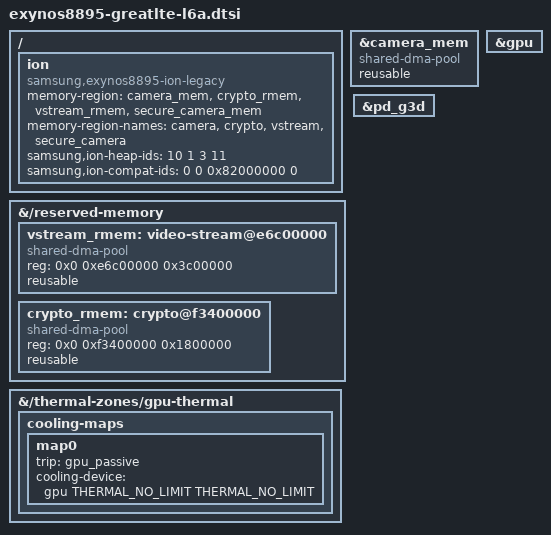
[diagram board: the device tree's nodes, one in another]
// SPDX-License-Identifier: GPL-2.0 OR BSD-3-Clause
/*
 * Samsung Galaxy Note 8 (greatlte, SM-N950N) board DT, part "l6a":
 * L6A graphics: GPU, ION (L6A 4).
 *
 * Included at the end of exynos8895-greatlte.dts, after L0's nodes, in the merge
 * order of FULL_IMAGE_PLAN.md 2.2. Owner: WP-6A; no other work package edits this
 * file (plan 2.3 rule D1). A node that two parts both configure (&usi9, &usi10)
 * is written identically in both files: dtc lets the later file win on a differing
 * value, which gl-verify V-DUP reports as an error. L0's reserved-memory stays in
 * the .dts; carveout additions and flag changes are &label edits here (plan X-8).
 */

/* ---- L6A slice ion: legacy ION heaps and their CMA pools (L6A 2.1 REQ-L0-6A-1, 2.4, 4.3) ---- */

/*
 * The ION camera heap (id 10) becomes a CMA pool owned by the ION shim (L6A 2.6):
 * rmem_cma_setup() takes only "reusable" shared-dma-pool nodes without no-map
 * (A:kernel/dma/contiguous.c:483-485). Stock kept it a carveout (FDT:36-40, no
 * "ion,reusable"; S:drivers/staging/android/ion/exynos/exynos_ion.c:451-453).
 * 0x880000000 / 0x15e00000 = 350 MiB, 2 MiB aligned: needs pageblock_order 9,
 * i.e. CONFIG_TRANSPARENT_HUGEPAGE=y (A:kernel/dma/contiguous.c:487-490; L6A 1.2).
 */
&camera_mem {
	compatible = "shared-dma-pool";
	reusable;
};

&{/reserved-memory} {
	/* ION vstream heap (id 3): FDT:56-63 video_stream, "ion,reusable" (:59), reg (:60) */
	vstream_rmem: video-stream@e6c00000 {
		compatible = "shared-dma-pool";
		reg = <0x0 0xe6c00000 0x3c00000>;	/* FDT:60 <0x00 0xe6c00000 0x3c00000>, 60 MiB */
		reusable;
	};

	/* ION crypto heap (id 1): FDT:65-70 crypto, "ion,reusable" (:67), reg (:68) */
	crypto_rmem: crypto@f3400000 {
		compatible = "shared-dma-pool";
		reg = <0x0 0xf3400000 0x1800000>;	/* FDT:68 <0x00 0xf3400000 0x1800000>, 24 MiB */
		reusable;
	};
};

/ {
	/*
	 * Legacy ION device (L6A 4.3, 5.2.8): root-level, so of_platform_default_populate
	 * creates it; stock "ion" node FDT:7459-7461. No iommus and no dma-coherent: it is
	 * the cache-maintenance proxy of L6A 5.2.5 item 8. Heap 0 (system) is implicit;
	 * secure_camera (id 11, FDT:42-47, "ion,secure") is the iris heap, protected through EL3
	 * (ion_legacy_heap.c); the HPA heaps 2/5/6/7/9 are not served.
	 */
	ion: ion {
		compatible = "samsung,exynos8895-ion-legacy";	/* new; stock "samsung,exynos5430-ion" FDT:7460 */
		memory-region = <&camera_mem>, <&crypto_rmem>, <&vstream_rmem>, <&secure_camera_mem>;
		/* heap names = name + "_heap" = the libion names camera_heap/crypto_heap/vstream_heap */
		memory-region-names = "camera", "crypto", "vstream", "secure_camera";
		samsung,ion-heap-ids = <10 1 3 11>;		/* FDT:39 <0x0a>, FDT:69 <0x01>, FDT:61 <0x03>, FDT:46 <0x0b> */
		/* FDT:62 compat-id = <0x19 0x1f> on video_stream: 1 << 25 | 1 << 31, as exynos_ion.c:406-411 */
		samsung,ion-compat-ids = <0 0 0x82000000 0>;
	};
};

/* L6A slice gpu: Mali-G71 kbase, pd_g3d, GPU cooling map (spec L6A_graphics.md 4.1, 4.2) */
&gpu {
	status = "okay";
};

/* REQ-L1-6A-1: the CMU_G3D pre-on/post-off hook is in the exynos8895-pd match data */
&pd_g3d {
	status = "okay";
};

&{/thermal-zones/gpu-thermal} {
	cooling-maps {
		map0 {
			trip = <&gpu_passive>;		/* 88000, FDT:9643 gpu-alert1 */
			cooling-device = <&gpu THERMAL_NO_LIMIT THERMAL_NO_LIMIT>;
		};
	};
};
